# PIC32MK0512MCJ048 device description
Architecture: MIPS; Family: PIC32MK; Series: PIC32MK
Registers are 32-bit, read-write, no defined reset value unless marked. A register's access mark holds for its fields unless they carry their own. Offsets are from the block's base; [hi:lo] are bit positions; {n}, {i} and the like mark numbered series.

## RCON
Instances: RCON 0x1f801200 in periph_pb1_std
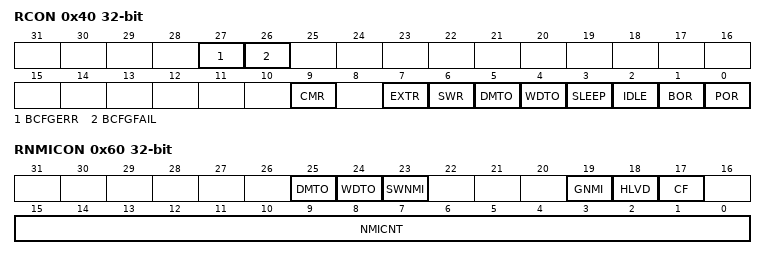
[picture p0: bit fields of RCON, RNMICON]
0x40 RCON — Reset Control Register
  [27] BCFGERR — Primary Configuration Registers Error Flag bit
    1=An error occurred during a read of the primary configuration registers; 0=No error occurred during a read of the primary configuration registers
  [26] BCFGFAIL — Primary/Secondary Configuration Registers Error Flag bit
    1=An error occurred during a read of the primary and alternate configuration registers; 0=No error occurred during a read of the primary and alternate configuration registers
  [9] CMR — Configuration Mismatch Reset Flag bit
    1=A Configuration Mismatch Reset has occurred; 0=A Configuration Mismatch Reset has not occurred
  [7] EXTR — External Reset (MCLR) Pin Flag bit
    1=Master Clear (pin) Reset has occurred; 0=Master Clear (pin) Reset has not occurred
  [6] SWR — Software Reset Flag bit
    1=Software Reset was executed; 0=Software Reset was not executed
  [5] DMTO — Deadman Timer Time-out Flag bit
    1=A DMT time-out has occurred; 0=A DMT time-out has not occurred
  [4] WDTO — Watchdog Timer Time-out Flag bit
    1=WDT Time-out has occurred; 0=WDT Time-out has not occurred
  [3] SLEEP — Wake From Sleep Flag bit
    1=Device was in Sleep mode; 0=Device was not in Sleep mode
  [2] IDLE — Wake From Idle Flag bit
    1=Device was in Idle mode; 0=Device was not in Idle mode
  [1] BOR — Brown-out Reset Flag bit
    1=Brown-out Reset has occurred; 0=Brown-out Reset has not occurred
  [0] POR — Power-on Reset Flag bit
    1=Power-on Reset has occurred; 0=Power-on Reset has not occurred
0x50 RSWRST wo — Software Reset Register
  [0] SWRST — Software Reset Trigger bit
    1=Enable software Reset event; 0=No effect
0x60 RNMICON — Non-maskable Interrupt (NMI) Control Register
  [25] DMTO — Deadman Timer Time-out Flag bit
    1=DMT time-out has occurred and caused a NMI; 0=DMT time-out has not occurred
  [24] WDTO — Watchdog Timer Time-Out Flag bit
    1=WDT time-out has occurred and caused a NMI; 0=WDT time-out has not occurred
  [23] SWNMI — Software NMI Trigger
    1=An NMI will be generated; 0=An NMI will not be generated
  [19] GNMI — General NMI bit
    1=A general NMI event has been detected or a user-initiated NMI event has occurred; 0=A general NMI event has not been detected
  [18] HLVD — High/Low-Voltage Detect Status
  [17] CF — Clock Fail Detect bit
    1=FSCM has detected clock failure and caused an NMI; 0=FSCM has not detected clock failure
  [15:0] NMICNT — NMI Reset Counter Value bits
    0xffff=65535 SYSCLK cycles before a device Reset occurs; 1=1 SYSCLK cycle before a device Reset occurs; 0=No delay between NMI assertion and device Reset event
0x70 PWRCON — Power Control Register
  [0] VREGS — Internal Voltage Regulator Stand-by Enable bit
Value list RNMICON__HLVD: 1=Indicates HLVD Event interrupt is active; 0=Indicates HLVD Event interrupt is not active
Value list PWRCON__VREGS: 1=Voltage regulator will remain active during Sleep; 0=Voltage regulator will go to Stand-by mode during Sleep

## CTMU
Instances: CTMU 0x1f82d000 in periph_pb2_std
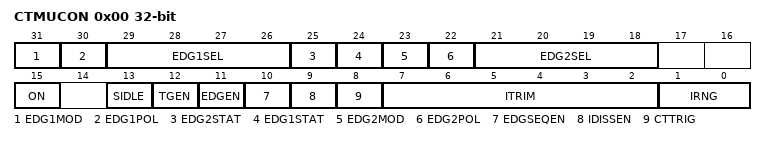
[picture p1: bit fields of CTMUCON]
0x00 CTMUCON — CTMU Control Register
  [31] EDG1MOD — Edge1 Edge Sampling Select bit
    0=Input is level-sensitive
  [30] EDG1POL — Edge 1 Polarity Select bit
    1=Edge1 programmed for a logic high level response; 0=Edge1 programmed for a logic low level response
  [29:26] EDG1SEL — Edge 1 Source Select bits
    15=C5OUT pin is selected; 14=C4OUT pin is selected; 13=C1OUT pin is selected; 12=PBCLK2 is selected; {v}=IC{v-6} Capture Event is selected (v=7..11); 6=OC4 Capture Event is selected; 5=OC3 Capture Event is selected; 4=OC2 Capture Event is selected; 3=CTED1 pin is selected; 2=CTED2 pin is selected; 1=OC1 Compare Event is selected; 0=Timer1 Event is selected
  [25] EDG2STAT — Edge2 Status bit
    1=Edge2 event has occurred; 0=Edge2 event has not occurred
  [24] EDG1STAT — Edge1 Status bit
    1=Edge1 event has occurred; 0=Edge1 event has not occurred
  [23] EDG2MOD — Edge2 Edge Sampling Select bit
    0=Input is level-sensitive
  [22] EDG2POL — Edge 2 Polarity Select bit
    1=Edge2 programmed for a high level response; 0=Edge2 programmed for a low level response
  [21:18] EDG2SEL — Edge 2 Source Select bits
    15=C5OUT Capture Event is selected; 14=C4OUT pin is selected; 13=C1OUT pin is selected; {v}=IC{v-6} Capture Event is selected (v=7..12); 6=OC4 Capture Event is selected; 5=OC3 Capture Event is selected; 4=OC2 Capture Event is selected; 3=CTED1 pin is selected; 2=CTED2 pin is selected; 1=OC1 Compare Event is selected; 0=Timer1 Event is selected
  [15] ON — ON Enable bit
    1=Module is enabled; 0=Module is disabled
  [13] SIDLE — Stop-in-Idle-Mode
    1=Discontinue Module Operation when device enters idle mode; 0=Continue module operation in idle mode
  [12] TGEN — Time Generation Enable bit
    1=Enables edge delay generation; 0=Disables edge delay generation
  [11] EDGEN — Edge Enable bit
    1=Edges are not blocked; 0=Edges are blocked
  [10] EDGSEQEN — Edge Sequence Enable bit
    1=Edge1 must occur before Edge2 can occur; 0=No edge sequence is needed
  [9] IDISSEN — Analog Current Source Control bit
    1=Analog current source output is grounded; 0=Analog current source output is not grounded
  [8] CTTRIG — Trigger Control bit
    1=Trigger output is enabled; 0=Trigger output is disabled
  [7:2] ITRIM — Current Source Trim bits
    31=Maximum positive change from nominal current; 1=Minimum positive change from nominal current; 0=Nominal current output specified by IRNG; 63=Minimum negative change from nominal current; 33=Maximum negative change from nominal current
  [1:0] IRNG — Current Range Select bits
    3=100 times base current; 2=10 times base current; 1=Base current level; 0=1000 times base current

## Notices in the file
Copyright (c) 2019 Microchip Technology Inc.
SPDX-License-Identifier: Apache-2.0
Licensed under the Apache License, Version 2.0 (the "License");
you may not use this file except in compliance with the License.
You may obtain a copy of the License at
http://www.apache.org/licenses/LICENSE-2.0
Unless required by applicable law or agreed to in writing, software
distributed under the License is distributed on an "AS IS" BASIS,
WITHOUT WARRANTIES OR CONDITIONS OF ANY KIND, either express or implied.
See the License for the specific language governing permissions and
limitations under the License.
